AUTOSAR XML (schema 4-3-0)
package /CAN7/ISignalGroup
  i signal group CAN7_SG_Door_Fr1: i-signal=[CAN7_Door_Fr_DoorEmergency_sta, CAN7_Door_Fr_Dooroperation_sta, CAN7_Door_Fr_Doorposition_sta], system-signal-group=CAN7_SG_Door_Fr1
  i signal group CAN7_SG_FD7_CE100_0: i-signal=[CAN7_FDC_BCM_FDDoorOpen_Sta, CAN7_LTurnLP, CAN7_RTurnLP], system-signal-group=CAN7_SG_FD7_CE100_0
  i signal group CAN7_SG_FD7_CE100_1: i-signal=[CAN7_FDC_BCM_FRClosedoor_Cmd, CAN7_FDC_BCM_FRHaltBrake_Sta, CAN7_FDC_BCM_FROpenClosePB_Cmd, CAN7_FDC_BCM_FROpendoor_Cmd, CAN7_FDC_BCM_PosLamp_Cmd, CAN7_FDC_FRDisIntEm_Cmd], system-signal-group=CAN7_SG_FD7_CE100_1
package /CAN7/Cluster
  can cluster CAN7: baudrate=500
    can physical channel CAN7: comm-connectors=ConnCAN7
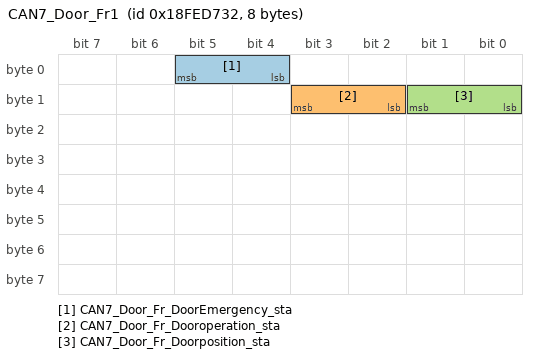
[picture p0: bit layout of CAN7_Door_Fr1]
      frame CAN7_Door_Fr1: id 0x18FED732, frame-length=8, can-addressing-mode=EXTENDED, can-fd-frame-support=false, can-frame-rx-behavior=CAN-20, can-frame-tx-behavior=CAN-20
        pdu CAN7_Door_Fr1: length=8, minimum-delay=0.0, transmission-mode-true-timing={cyclic-timing=time-period=0.1, event-controlled-timing={number-of-repetitions=0, repetition-period=0}}, unused-bit-pattern=0
          mapping CAN7_SG_Door_Fr1: i-signal-group=CAN7_SG_Door_Fr1, start-position=0, transfer-property=TRIGGERED-ON-CHANGE
          signal CAN7_Door_Fr_DoorEmergency_sta: start 4, 2 bit, little-endian, i-signal-type=PRIMITIVE, init-value=constant-reference=Init_CAN7_Door_Fr_DoorEmergency_sta, base-type=uint8, implementation-data-type=uint8, transfer-property=TRIGGERED-ON-CHANGE
          signal CAN7_Door_Fr_Dooroperation_sta: start 10, 2 bit, little-endian, i-signal-type=PRIMITIVE, init-value=constant-reference=Init_CAN7_Door_Fr_Dooroperation_sta, base-type=uint8, implementation-data-type=uint8, transfer-property=TRIGGERED-ON-CHANGE
          signal CAN7_Door_Fr_Doorposition_sta: start 8, 2 bit, little-endian, i-signal-type=PRIMITIVE, init-value=constant-reference=Init_CAN7_Door_Fr_Doorposition_sta, base-type=uint8, implementation-data-type=uint8, transfer-property=TRIGGERED-ON-CHANGE
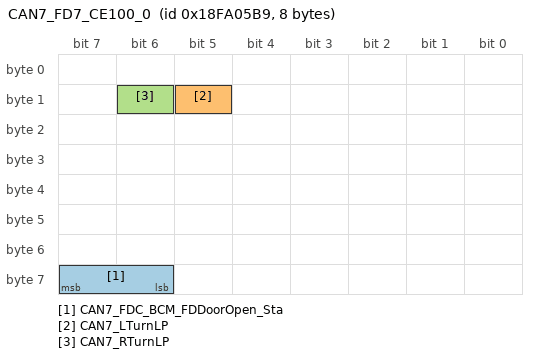
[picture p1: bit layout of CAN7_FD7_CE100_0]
      frame CAN7_FD7_CE100_0: id 0x18FA05B9, frame-length=8, can-addressing-mode=EXTENDED, can-fd-frame-support=false, can-frame-rx-behavior=CAN-20, can-frame-tx-behavior=CAN-20
        pdu CAN7_FD7_CE100_0: length=8, minimum-delay=0.0, transmission-mode-true-timing={cyclic-timing=time-period=0.1, event-controlled-timing={number-of-repetitions=0, repetition-period=0}}, unused-bit-pattern=0
          mapping CAN7_SG_FD7_CE100_0: i-signal-group=CAN7_SG_FD7_CE100_0, start-position=0, transfer-property=TRIGGERED-ON-CHANGE
          signal CAN7_FDC_BCM_FDDoorOpen_Sta: start 62, 2 bit, little-endian, i-signal-type=PRIMITIVE, init-value=constant-reference=Init_CAN7_FDC_BCM_FDDoorOpen_Sta, base-type=uint8, implementation-data-type=uint8, transfer-property=TRIGGERED-ON-CHANGE
          signal CAN7_LTurnLP: start 13, 1 bit, little-endian, i-signal-type=PRIMITIVE, init-value=constant-reference=Init_CAN7_LTurnLP, base-type=uint8, implementation-data-type=uint8, transfer-property=TRIGGERED-ON-CHANGE
          signal CAN7_RTurnLP: start 14, 1 bit, little-endian, i-signal-type=PRIMITIVE, init-value=constant-reference=Init_CAN7_RTurnLP, base-type=uint8, implementation-data-type=uint8, transfer-property=TRIGGERED-ON-CHANGE
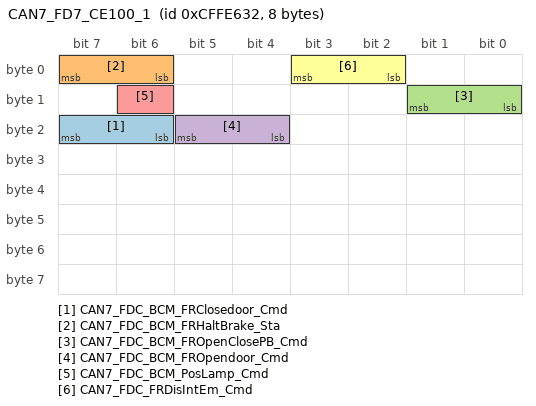
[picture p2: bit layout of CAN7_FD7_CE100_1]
      frame CAN7_FD7_CE100_1: id 0xCFFE632, frame-length=8, can-addressing-mode=EXTENDED, can-fd-frame-support=false, can-frame-rx-behavior=CAN-20, can-frame-tx-behavior=CAN-20
        pdu CAN7_FD7_CE100_1: length=8, minimum-delay=0.0, transmission-mode-true-timing={cyclic-timing=time-period=0.1, event-controlled-timing={number-of-repetitions=0, repetition-period=0}}, unused-bit-pattern=0
          mapping CAN7_SG_FD7_CE100_1: i-signal-group=CAN7_SG_FD7_CE100_1, start-position=0, transfer-property=TRIGGERED-ON-CHANGE
          signal CAN7_FDC_BCM_FRClosedoor_Cmd: start 22, 2 bit, little-endian, i-signal-type=PRIMITIVE, init-value=constant-reference=Init_CAN7_FDC_BCM_FRClosedoor_Cmd, base-type=uint8, implementation-data-type=uint8, transfer-property=TRIGGERED-ON-CHANGE
          signal CAN7_FDC_BCM_FRHaltBrake_Sta: start 6, 2 bit, little-endian, i-signal-type=PRIMITIVE, init-value=constant-reference=Init_CAN7_FDC_BCM_FRHaltBrake_Sta, base-type=uint8, implementation-data-type=uint8, transfer-property=TRIGGERED-ON-CHANGE
          signal CAN7_FDC_BCM_FROpenClosePB_Cmd: start 8, 2 bit, little-endian, i-signal-type=PRIMITIVE, init-value=constant-reference=Init_CAN7_FDC_BCM_FROpenClosePB_Cmd, base-type=uint8, implementation-data-type=uint8, transfer-property=TRIGGERED-ON-CHANGE
          signal CAN7_FDC_BCM_FROpendoor_Cmd: start 20, 2 bit, little-endian, i-signal-type=PRIMITIVE, init-value=constant-reference=Init_CAN7_FDC_BCM_FROpendoor_Cmd, base-type=uint8, implementation-data-type=uint8, transfer-property=TRIGGERED-ON-CHANGE
          signal CAN7_FDC_BCM_PosLamp_Cmd: start 14, 1 bit, little-endian, i-signal-type=PRIMITIVE, init-value=constant-reference=Init_CAN7_FDC_BCM_PosLamp_Cmd, base-type=uint8, implementation-data-type=uint8, transfer-property=TRIGGERED-ON-CHANGE
          signal CAN7_FDC_FRDisIntEm_Cmd: start 2, 2 bit, little-endian, i-signal-type=PRIMITIVE, init-value=constant-reference=Init_CAN7_FDC_FRDisIntEm_Cmd, base-type=uint8, implementation-data-type=uint8, transfer-property=TRIGGERED-ON-CHANGE
package /CAN7/ConstantSpecification
  15 x constant specification:
    Init_CAN7_Door_Fr_DoorEmergency_sta: value-spec=0
    Init_CAN7_Door_Fr_Dooroperation_sta: value-spec=0
    Init_CAN7_Door_Fr_Doorposition_sta: value-spec=0
    Init_CAN7_FDC_BCM_FDDoorOpen_Sta: value-spec=0
    Init_CAN7_LTurnLP: value-spec=0
    Init_CAN7_RTurnLP: value-spec=0
    Init_CAN7_FDC_BCM_FRClosedoor_Cmd: value-spec=0
    Init_CAN7_FDC_BCM_FRHaltBrake_Sta: value-spec=0
    Init_CAN7_FDC_BCM_FROpenClosePB_Cmd: value-spec=0
    Init_CAN7_FDC_BCM_FROpendoor_Cmd: value-spec=0
    Init_CAN7_FDC_BCM_PosLamp_Cmd: value-spec=0
    Init_CAN7_FDC_FRDisIntEm_Cmd: value-spec=0
    Init_CAN7_SG_Door_Fr1: value-spec=fields=[Init_CAN7_Door_Fr_DoorEmergency_sta, Init_CAN7_Door_Fr_Dooroperation_sta, Init_CAN7_Door_Fr_Doorposition_sta]
    Init_CAN7_SG_FD7_CE100_0: value-spec=fields=[Init_CAN7_FDC_BCM_FDDoorOpen_Sta, Init_CAN7_LTurnLP, Init_CAN7_RTurnLP]
    Init_CAN7_SG_FD7_CE100_1: value-spec=fields=[Init_CAN7_FDC_BCM_FRClosedoor_Cmd, Init_CAN7_FDC_BCM_FRHaltBrake_Sta, Init_CAN7_FDC_BCM_FROpenClosePB_Cmd, Init_CAN7_FDC_BCM_FROpendoor_Cmd, Init_CAN7_FDC_BCM_PosLamp_Cmd, Init_CAN7_FDC_FRDisIntEm_Cmd]
package /CAN7/ImplementationDataTypes
  impl type DT_CAN7_SG_Door_Fr1: category=STRUCTURE
    element CAN7_Door_Fr_DoorEmergency_sta: implementation-data-type=uint8
    element CAN7_Door_Fr_Dooroperation_sta: implementation-data-type=uint8
    element CAN7_Door_Fr_Doorposition_sta: implementation-data-type=uint8
  impl type DT_CAN7_SG_FD7_CE100_0: category=STRUCTURE
    element CAN7_FDC_BCM_FDDoorOpen_Sta: implementation-data-type=uint8
    element CAN7_LTurnLP: implementation-data-type=uint8
    element CAN7_RTurnLP: implementation-data-type=uint8
  impl type DT_CAN7_SG_FD7_CE100_1: category=STRUCTURE
    6 x element, all with category=TYPE_REFERENCE, implementation-data-type=uint8:
      CAN7_FDC_BCM_FRClosedoor_Cmd
      CAN7_FDC_BCM_FRHaltBrake_Sta
      CAN7_FDC_BCM_FROpenClosePB_Cmd
      CAN7_FDC_BCM_FROpendoor_Cmd
      CAN7_FDC_BCM_PosLamp_Cmd
      CAN7_FDC_FRDisIntEm_Cmd
